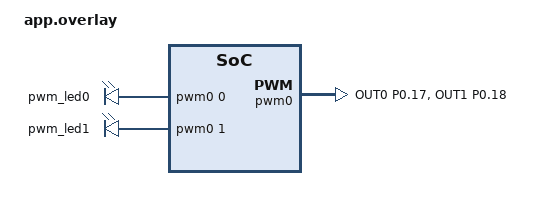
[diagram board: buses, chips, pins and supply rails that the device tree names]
/ {
	pwmleds {
		compatible = "pwm-leds";
		pwm_led0: pwm_led_0 {
			pwms = <&pwm0 0 PWM_MSEC(20) PWM_POLARITY_INVERTED>;
		};
        pwm_led1: pwm_led_1 {
			pwms = <&pwm0 1 PWM_MSEC(20) PWM_POLARITY_INVERTED>;
		};
	};
    aliases {
		pwm-led0 = &pwm_led0;
		pwm-led1 = &pwm_led1;
	};
};

&pinctrl {
	pwm0_default: pwm0_default {
		group1 {
			psels = <NRF_PSEL(PWM_OUT0, 0, 17)>, <NRF_PSEL(PWM_OUT1, 0, 18)>;
			nordic,invert;
		};
	};

	pwm0_sleep: pwm0_sleep {
		group1 {
			psels = <NRF_PSEL(PWM_OUT0, 0, 17)>, <NRF_PSEL(PWM_OUT1, 0, 18)>;
			low-power-enable;
		};
	};
};

&pwm0 {
	status = "okay";
	pinctrl-0 = <&pwm0_default>;
	pinctrl-1 = <&pwm0_sleep>;
	pinctrl-names = "default", "sleep";
};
